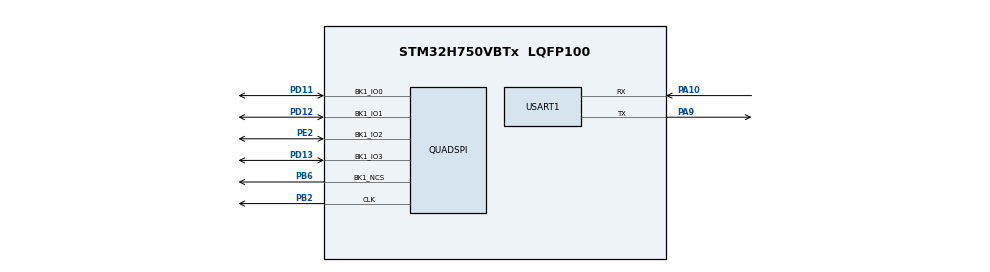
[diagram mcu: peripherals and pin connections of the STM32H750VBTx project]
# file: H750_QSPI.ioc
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CORTEX_M7.default_mode_Activation=1
Mcu.Family=STM32H7
Mcu.Name=STM32H750VBTx
Mcu.Package=LQFP100
NVIC.PriorityGroup=NVIC_PRIORITYGROUP_4
PA10.Mode=Asynchronous
PA10.Signal=USART1_RX
PA13\ (JTMS/SWDIO).Mode=Serial_Wire
PA13\ (JTMS/SWDIO).Signal=DEBUG_JTMS-SWDIO
PA14\ (JTCK/SWCLK).Mode=Serial_Wire
PA14\ (JTCK/SWCLK).Signal=DEBUG_JTCK-SWCLK
PA9.Mode=Asynchronous
PA9.Signal=USART1_TX
PB2.GPIO_Speed=GPIO_SPEED_FREQ_VERY_HIGH
PB2.Mode=Single Bank 1
PB2.Signal=QUADSPI_CLK
PB6.GPIO_Speed=GPIO_SPEED_FREQ_VERY_HIGH
PB6.Mode=Single Bank 1
PB6.Signal=QUADSPI_BK1_NCS
PD11.GPIO_Speed=GPIO_SPEED_FREQ_VERY_HIGH
PD11.Mode=Single Bank 1
PD11.Signal=QUADSPI_BK1_IO0
PD12.GPIO_Speed=GPIO_SPEED_FREQ_VERY_HIGH
PD12.Mode=Single Bank 1
PD12.Signal=QUADSPI_BK1_IO1
PD13.GPIO_Speed=GPIO_SPEED_FREQ_VERY_HIGH
PD13.Mode=Single Bank 1
PD13.Signal=QUADSPI_BK1_IO3
PE2.GPIO_Speed=GPIO_SPEED_FREQ_VERY_HIGH
PE2.Mode=Single Bank 1
PE2.Signal=QUADSPI_BK1_IO2
ProjectManager.HeapSize=0x200
ProjectManager.StackSize=0x400
ProjectManager.TargetToolchain=MDK-ARM V5.32
QUADSPI.ClockMode=QSPI_CLOCK_MODE_3
QUADSPI.ClockPrescaler=1
QUADSPI.FifoThreshold=32
QUADSPI.FlashSize=22
QUADSPI.SampleShifting=QSPI_SAMPLE_SHIFTING_HALFCYCLE
RCC.ADCFreq_Value=120000000
RCC.APB1Freq_Value=120000000
RCC.APB2Freq_Value=120000000
RCC.APB3Freq_Value=120000000
RCC.APB4Freq_Value=120000000
RCC.CortexFreq_Value=480000000
RCC.D1PPRE=RCC_APB3_DIV2
RCC.D2PPRE1=RCC_APB1_DIV2
RCC.D2PPRE2=RCC_APB2_DIV2
RCC.D3PPRE=RCC_APB4_DIV2
RCC.DIVM1=4
RCC.DIVM2=4
RCC.DIVN1=60
RCC.DIVN2=15
RCC.DIVR2=1
RCC.HCLKFreq_Value=240000000
RCC.HPRE=RCC_HCLK_DIV2
RCC.PLL2FRACN=0
RCC.PLLFRACN=0
RCC.QSPICLockSelection=RCC_QSPICLKSOURCE_PLL2
RCC.SYSCLKFreq_VALUE=480000000
RCC.SYSCLKSource=RCC_SYSCLKSOURCE_PLLCLK
RCC.USBFreq_Value=480000000
USART1.VirtualMode-Asynchronous=VM_ASYNC
VP_MEMORYMAP_VS_MEMORYMAP.Mode=CurAppReg
board=custom

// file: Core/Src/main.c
/* USER CODE BEGIN Header */
/**
 ******************************************************************************
 * @file           : main.c
 * @brief          : Main program body
 ******************************************************************************
 * @attention
 *
 * Copyright (c) 2024 STMicroelectronics.
 * All rights reserved.
 *
 * This software is licensed under terms that can be found in the LICENSE file
 * in the root directory of this software component.
 * If no LICENSE file comes with this software, it is provided AS-IS.
 *
 ******************************************************************************
 */
/* USER CODE END Header */
#include "main.h"
#include "memorymap.h"
#include "quadspi.h"
#include "usart.h"
#include "gpio.h"
#include "stdio.h"
/* USER CODE BEGIN Includes */
#include "qspi_w25q64.h"
/* USER CODE END Includes */

/* USER CODE BEGIN PV */
extern QSPI_HandleTypeDef hqspi;
/* USER CODE END PV */

void SystemClock_Config(void);
static void MPU_Config(void);

/* USER CODE BEGIN 0 */
uint8_t a;
/* USER CODE END 0 */

int main(void)
{

  /* USER CODE BEGIN 1 */
  SCB_EnableICache();
  SCB_EnableDCache();
  /* USER CODE END 1 */

  /* MPU Configuration--------------------------------------------------------*/
  MPU_Config();

  /* MCU Configuration--------------------------------------------------------*/

  /* Reset of all peripherals, Initializes the Flash interface and the Systick. */
  HAL_Init();

  /* Configure the system clock */
  SystemClock_Config();

  /* Initialize all configured peripherals */
  MX_GPIO_Init();
  MX_QUADSPI_Init();
  MX_USART1_UART_Init();
  /* USER CODE BEGIN 2 */
  QSPI_W25Qxx_Init(&hqspi);
  QSPI_W25Qxx_Test(&hqspi);
  /* USER CODE END 2 */

  /* Infinite loop */
  while (1)
  {

  }
}

void SystemClock_Config(void)
{
  RCC_OscInitTypeDef RCC_OscInitStruct = {0};
  RCC_ClkInitTypeDef RCC_ClkInitStruct = {0};

  /** Supply configuration update enable
   */
  HAL_PWREx_ConfigSupply(PWR_LDO_SUPPLY);

  /** Configure the main internal regulator output voltage
   */
  __HAL_PWR_VOLTAGESCALING_CONFIG(PWR_REGULATOR_VOLTAGE_SCALE1);

  while (!__HAL_PWR_GET_FLAG(PWR_FLAG_VOSRDY))
  {
  }

  __HAL_RCC_SYSCFG_CLK_ENABLE();
  __HAL_PWR_VOLTAGESCALING_CONFIG(PWR_REGULATOR_VOLTAGE_SCALE0);

  while (!__HAL_PWR_GET_FLAG(PWR_FLAG_VOSRDY))
  {
  }

  /** Initializes the RCC Oscillators according to the specified parameters
   * in the RCC_OscInitTypeDef structure.
   */
  RCC_OscInitStruct.OscillatorType = RCC_OSCILLATORTYPE_HSI;
  RCC_OscInitStruct.HSIState = RCC_HSI_DIV1;
  RCC_OscInitStruct.HSICalibrationValue = RCC_HSICALIBRATION_DEFAULT;
  RCC_OscInitStruct.PLL.PLLState = RCC_PLL_ON;
  RCC_OscInitStruct.PLL.PLLSource = RCC_PLLSOURCE_HSI;
  RCC_OscInitStruct.PLL.PLLM = 4;
  RCC_OscInitStruct.PLL.PLLN = 60;
  RCC_OscInitStruct.PLL.PLLP = 2;
  RCC_OscInitStruct.PLL.PLLQ = 2;
  RCC_OscInitStruct.PLL.PLLR = 2;
  RCC_OscInitStruct.PLL.PLLRGE = RCC_PLL1VCIRANGE_3;
  RCC_OscInitStruct.PLL.PLLVCOSEL = RCC_PLL1VCOWIDE;
  RCC_OscInitStruct.PLL.PLLFRACN = 0;
  if (HAL_RCC_OscConfig(&RCC_OscInitStruct) != HAL_OK)
  {
    Error_Handler();
  }

  /** Initializes the CPU, AHB and APB buses clocks
   */
  RCC_ClkInitStruct.ClockType = RCC_CLOCKTYPE_HCLK | RCC_CLOCKTYPE_SYSCLK | RCC_CLOCKTYPE_PCLK1 | RCC_CLOCKTYPE_PCLK2 | RCC_CLOCKTYPE_D3PCLK1 | RCC_CLOCKTYPE_D1PCLK1;
  RCC_ClkInitStruct.SYSCLKSource = RCC_SYSCLKSOURCE_PLLCLK;
  RCC_ClkInitStruct.SYSCLKDivider = RCC_SYSCLK_DIV1;
  RCC_ClkInitStruct.AHBCLKDivider = RCC_HCLK_DIV2;
  RCC_ClkInitStruct.APB3CLKDivider = RCC_APB3_DIV2;
  RCC_ClkInitStruct.APB1CLKDivider = RCC_APB1_DIV2;
  RCC_ClkInitStruct.APB2CLKDivider = RCC_APB2_DIV2;
  RCC_ClkInitStruct.APB4CLKDivider = RCC_APB4_DIV2;

  if (HAL_RCC_ClockConfig(&RCC_ClkInitStruct, FLASH_LATENCY_4) != HAL_OK)
  {
    Error_Handler();
  }
}

/* MPU Configuration */

void MPU_Config(void)
{
  MPU_Region_InitTypeDef MPU_InitStruct = {0};

  /* Disables the MPU */
  HAL_MPU_Disable();

  /** Initializes and configures the Region and the memory to be protected
   */
  MPU_InitStruct.Enable = MPU_REGION_ENABLE;
  MPU_InitStruct.Number = MPU_REGION_NUMBER0;
  MPU_InitStruct.BaseAddress = 0x0;
  MPU_InitStruct.Size = MPU_REGION_SIZE_4GB;
  MPU_InitStruct.SubRegionDisable = 0x87;
  MPU_InitStruct.TypeExtField = MPU_TEX_LEVEL0;
  MPU_InitStruct.AccessPermission = MPU_REGION_NO_ACCESS;
  MPU_InitStruct.DisableExec = MPU_INSTRUCTION_ACCESS_DISABLE;
  MPU_InitStruct.IsShareable = MPU_ACCESS_SHAREABLE;
  MPU_InitStruct.IsCacheable = MPU_ACCESS_NOT_CACHEABLE;
  MPU_InitStruct.IsBufferable = MPU_ACCESS_NOT_BUFFERABLE;

  HAL_MPU_ConfigRegion(&MPU_InitStruct);
  /* Enables the MPU */
  HAL_MPU_Enable(MPU_PRIVILEGED_DEFAULT);
}

void Error_Handler(void)
{
  __disable_irq();
  while (1)
  {
  }
}
